# OsciArty register map
File version: 0.8
BearlyML on Arty
CPU: RISCV r1p1, little endian, no MPU, no FPU, 4 interrupt priority bits
Registers are 32-bit, read-write, reset 0x0 unless marked. A register's access mark holds for its fields unless they carry their own. Offsets are from the block's base; lines under a group give offsets from that group; [hi:lo] are bit positions; {n}, {i} and the like mark numbered series; 'fields as' and 'values as' point back to an identical list; <NAME> marks a mode.

## Memory map
0x00002000 PLL size 0x400 — Phase locked loop
0x00004000 BOOT_SELECT size 0x400 — Boot Selection Pin
0x00100000 RCC size 0x400 — Reset and Clock Control
0x02000000 CLINT size 0x400 — Core-Local Interruptor
0x10012000 GPIOA size 0x400 — General purpose I/O
0x1001A000 UART0 size 0x400 — Universal Asynchronous Receiver/Transmitter
0x10020000 QSPI0 size 0x400 — Serial Peripheral Interface
0x10024000 I2C0 size 0x400 — Inter-Integrated Circuit
0x10025000 I2C1 size 0x400

## PLL — Phase locked loop
Base 0x00002000
0x00 LOOP_PHASEACQENABLE
  [0] ENABLE
    1=Enabled; 0=Disabled
0x04 LOOP_UPD_TS
  [1:0] UPD_TS
0x08 LOOP_ALG_EN
  [0] EN
0x0C LOOP_DSM_EN
  [0] EN
0x10 LOOP_DCOCTRLCODEOVERRIDE
  [7:0] OVERRIDE
0x14 LOOP_DLF_IC
  [7:0] DLF_IC
0x18 LOOP_ALG_IC
  [7:0] ALG_IC
0x1C LOOP_ALG_GA
  [3:0] ALG_GA
0x20 LOOP_ALG_CF
  [3:0] ALG_CF
0x24 LOOP_DLF_KP
  [3:0] DLF_KP
0x28 LOOP_DLF_KI
  [3:0] DLF_KI
0x2C BPD_PD
  [0] BPD_PD
0x30 DIV_SEL_CLK_DLF
  [1:0] DIV_SEL_CLK_DLF
0x34 DIV_SEL_CLK_DIV
  [1:0] DIV_SEL_CLK_DIV
0x38 DIV_PD
  [0] DIV_PD

## BOOT_SELECT — Boot Selection Pin
Base 0x00004000
0x00 BOOT_SEL ro — boot select
  [0] VAL0 — Input value of pin 0
    1=Self-Boot Mode; 0=Tethered Boot Mode

## CLINT — Core-Local Interruptor
Base 0x02000000
{0x0+4i} MSIP{i} (i=0..4) — hart {i} msip bit
  [0] MSIP{i} — hart {i} machine mode software interrupt in progress
    1=Interrupt pending (Self-Boot Mode); 0=No interrupt (Tethered Boot Mode)
{0x4000+8i} MTIMECMP{i} (i=0..4) — hart {i} mtimecmp value
  [63:0] MTIMECMP{i} — hart {i} machine mode timer compare value
0xBFF8 MTIME — mtime value
  [63:0] MTIME — machine mode timer value

## RCC — Reset and Clock Control
Base 0x00100000
{0x0+4i} TILE{i}_RESET (i=0..3) — RocketTile {i} reset control
  [0] TILE{i}_RESET
0x10 TILE4_RESET — SaturnTile reset control
  [0] TILE4_RESET
0x2000 CLK_SEL — Clock selection
  [0] SEL — Selects the system clock
    1=PLL Clock (Select PLL clock); 0=External Clock (Select external clock)
0x2008 DEBUG_CLK_SEL — input value
  [0] SEL — Selection
0x200C DEBUG_CLK_DIV — input value
  [11:0] DIV — Clock divisor

## GPIOA — General purpose I/O
Base 0x10012000
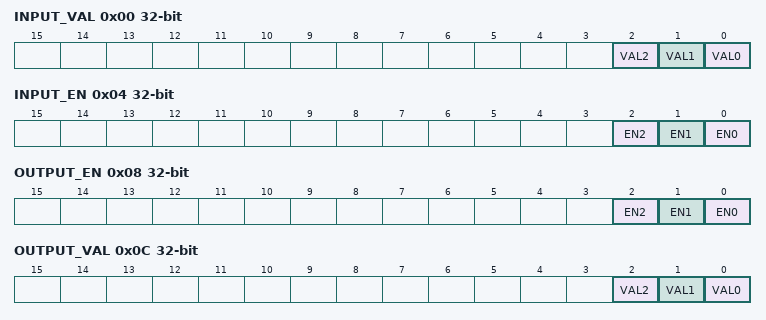
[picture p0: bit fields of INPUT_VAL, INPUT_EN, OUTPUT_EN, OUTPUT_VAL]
0x00 INPUT_VAL ro — input value
  [2] VAL2 — Input value of pin 2
  [1] VAL1 — Input value of pin 1
  [0] VAL0 — Input value of pin 0
0x04 INPUT_EN — input enable
  [all] fields
    1=Enabled (Enable input); 0=Disabled (Disable input)
  [2] EN2 — Input enable control of pin 2
  [1] EN1 — Input enable control of pin 1
  [0] EN0 — Input enable control of pin 0
0x08 OUTPUT_EN — output enable
  [all] fields
    1=Enabled (Enable output); 0=Disabled (Disable output)
  [2] EN2 — Output enable control of pin 2
  [1] EN1 — Output enable control of pin 1
  [0] EN0 — Output enable control of pin 0
0x0C OUTPUT_VAL — output value
  [all] fields
    1=High (Set output to logic high); 0=Low (Set output to logic low)
  [2] VAL2 — Output value of pin 2
  [1] VAL1 — Output value of pin 1
  [0] VAL0 — Output value of pin 0

## UART0 — Universal Asynchronous Receiver/Transmitter
Base 0x1001A000
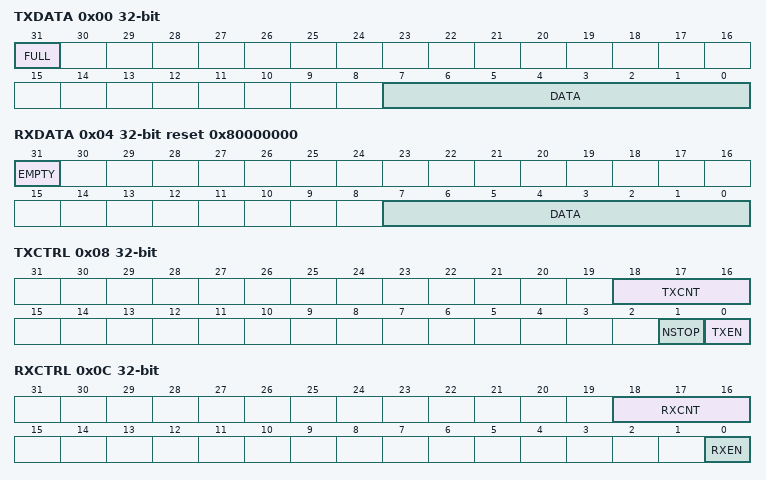
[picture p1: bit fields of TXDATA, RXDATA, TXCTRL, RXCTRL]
0x00 TXDATA — transmit data register
  [31] FULL — Transmit FIFO full
    1=Full (Transmit FIFO is full); 0=Not full (Transmit FIFO is not full)
  [7:0] DATA — Transmit data
0x04 RXDATA ro reset 0x80000000 — receive data register
  [31] EMPTY — Receive FIFO empty
    1=Empty (Receive FIFO is empty); 0=Not empty (Receive FIFO is not empty)
  [7:0] DATA — Received data
0x08 TXCTRL — transmit control register
  [18:16] TXCNT — Transmit watermark level
  [1] NSTOP — Number of stop bits
    1=2 stop bits; 0=1 stop bit
  [0] TXEN — Transmit enable
    1=Enabled (Transmit enabled); 0=Disabled (Transmit disabled)
0x0C RXCTRL — receive control register
  [18:16] RXCNT — Receive watermark level
  [0] RXEN — Receive enable
    1=Enabled (Receive enabled); 0=Disabled (Receive disabled)
0x18 DIV reset 0xAD — baudrate divisor
  [15:0] DIV — Baudrate divisor

## QSPI0 — Serial Peripheral Interface
Base 0x10020000
0x00 SCKDIV reset 0x3 — serial clock divisor
  [11:0] DIV — Divisor for serial clock
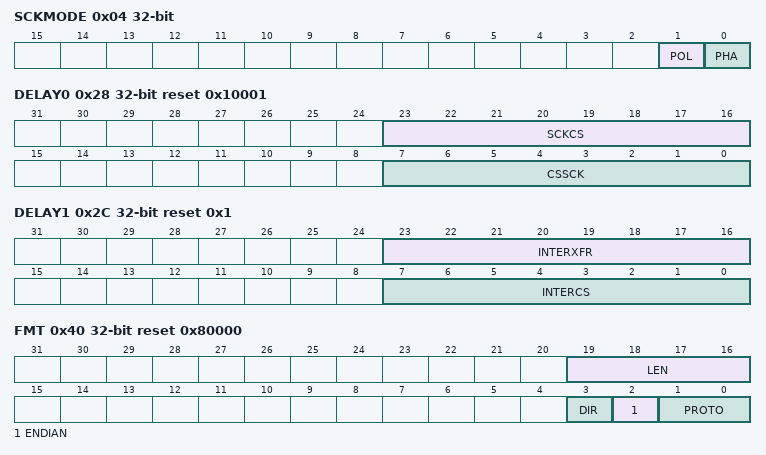
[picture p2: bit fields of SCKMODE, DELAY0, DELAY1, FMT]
0x04 SCKMODE — serial clock mode
  [1] POL — Serial clock polarity
    1=Sample on 2nd edge (Data is sampled at second edge of SCLK); 0=Sample on 1st edge (Data is sampled at first edge of SCLK)
  [0] PHA — Serial clock phase
    1=Idle High (SCLK idle state is high); 0=Idle Low (SCLK idle state is low)
0x10 CSID — chip select ID
  [31:0] CSID — Chip select ID.
0x14 CSDEF — chip select default value
  [31:0] CSDEF — Chip select default value
0x18 CSMODE — chip select mode
  [1:0] MODE — Chip select mode
    2=OFF (Disable hardware control of the CS pin); 1=HOLD (Keep CS continuously asserted after the initial frame); 0=AUTO (Assert/deassert CS at the beginning/end of each frame)
0x28 DELAY0 reset 0x10001 — delay control 0
  [23:16] SCKCS — SCK to CS delay
  [7:0] CSSCK — CS to SCK delay
0x2C DELAY1 reset 0x1 — delay control 1
  [23:16] INTERXFR — Maximum interframe delay
  [7:0] INTERCS — Minimum CS inactive time
0x40 FMT reset 0x80000 — frame format
  [19:16] LEN — number of bits per frame
  [3] DIR — SPI I/O direction
    1=TX (The receive FIFO is not populated); 0=RX (For dual and quad protocols, the DQ pins are tri-stated. For the single protocol, the DQ0 pin is driven with the transmit data as normal.)
  [2] ENDIAN — SPI endianess
    1=LSB (least-significant bit first); 0=MSB (most-significant bit first)
  [1:0] PROTO — SPI protocol
    2=QuadSPI mode, use DQ0, DQ1, DQ2, DQ3; 1=DualSPI mode, use DQ0, DQ1; 0=Single SPI mode, use DQ0 as MOSI, DQ1 as MISO
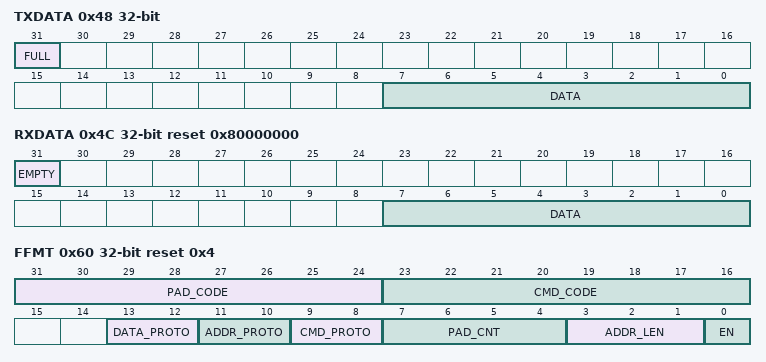
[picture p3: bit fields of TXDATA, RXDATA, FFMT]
0x48 TXDATA — transmit data
  [31] FULL — Transmit FIFO full
    1=Full (Transmit FIFO is full); 0=Not full (Transmit FIFO is not full)
  [7:0] DATA — Transmit data
0x4C RXDATA ro reset 0x80000000 — receive data register
  [31] EMPTY — Receive FIFO empty
    1=Empty (Receive FIFO is empty); 0=Not empty (Receive FIFO is not empty)
  [7:0] DATA — Received data
0x60 FCTRL reset 0x1 — Flash interface control
  [0] EN — SPI Flash mode select
    1=Enabled (Flash mode enabled); 0=Disabled (Flash mode disabled)
0x60 FFMT reset 0x4 — Flash instruction format
  [31:24] PAD_CODE — First 8 bits to transmit during dummy cycles
  [23:16] CMD_CODE — Value of command byte
  [13:12] DATA_PROTO — Protocol for receiving data
  [11:10] ADDR_PROTO — Protocol for transmitting address and padding
  [9:8] CMD_PROTO — Protocol for transmitting command
  [7:4] PAD_CNT — Number of dummy cycles
  [3:1] ADDR_LEN — Number of address bytes
  [0] EN — enable sending of command
    1=Enabled (command enabled); 0=Disabled (command disabled)

## I2C0 — Inter-Integrated Circuit
Base 0x10024000
Same registers: I2C1 0x10025000
0x00 PRESCAL_LO reset 0xFF
  [7:0] PRESCAL_LO
0x04 PRESCAL_HI reset 0xFF
  [7:0] PRESCAL_HI
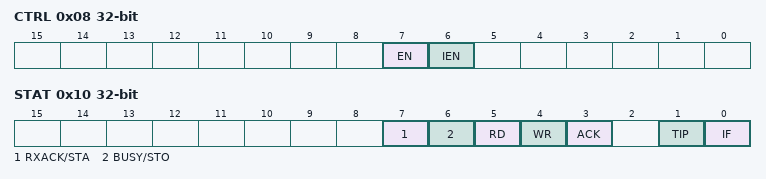
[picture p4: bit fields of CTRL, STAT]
0x08 CTRL
  [7] EN — enable
  [6] IEN — interrupt enable
0x0C DATA
  [7:0] DATA
0x10 STAT
  [7] RXACK/STA — acknowledge status / start condition
  [6] BUSY/STO — busy / stop condition
  [5] RD — read from slave
  [4] WR — write to slave
  [3] ACK — acknowledge bit enabled
  [1] TIP — transfer in progress
  [0] IF — interrupt pending
